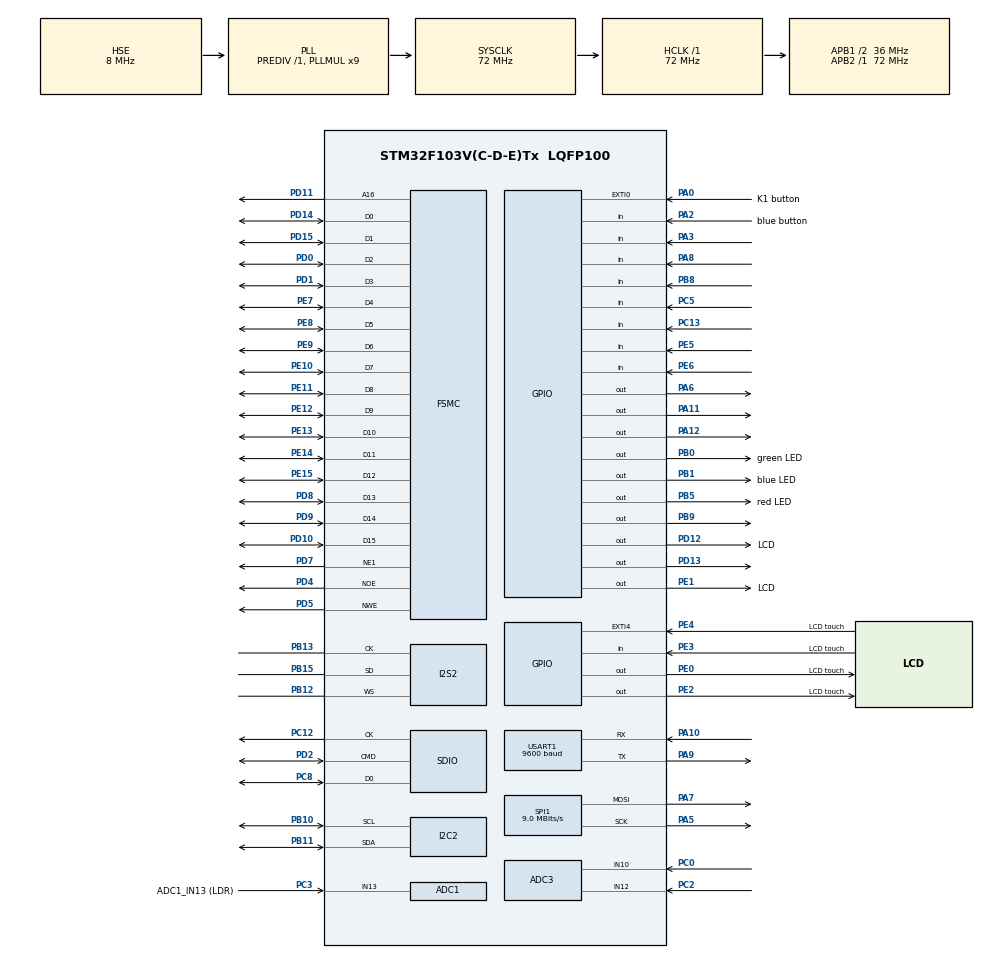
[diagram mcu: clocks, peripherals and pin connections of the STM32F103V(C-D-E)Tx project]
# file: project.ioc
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ADC1.Channel-0\#ChannelRegularConversion=ADC_CHANNEL_13
ADC1.NbrOfConversionFlag=1
ADC1.Rank-0\#ChannelRegularConversion=1
ADC1.SamplingTime-0\#ChannelRegularConversion=ADC_SAMPLETIME_1CYCLE_5
ADC1.master=1
ADC3.Channel-0\#ChannelRegularConversion=ADC_CHANNEL_10
ADC3.Channel-1\#ChannelRegularConversion=ADC_CHANNEL_12
ADC3.ContinuousConvMode=ENABLE
ADC3.NbrOfConversion=2
ADC3.NbrOfConversionFlag=1
ADC3.Rank-0\#ChannelRegularConversion=1
ADC3.Rank-1\#ChannelRegularConversion=2
ADC3.SamplingTime-0\#ChannelRegularConversion=ADC_SAMPLETIME_239CYCLES_5
ADC3.SamplingTime-1\#ChannelRegularConversion=ADC_SAMPLETIME_239CYCLES_5
Dma.ADC3.0.Direction=DMA_PERIPH_TO_MEMORY
Dma.ADC3.0.Instance=DMA2_Channel5
Dma.ADC3.0.MemDataAlignment=DMA_MDATAALIGN_WORD
Dma.ADC3.0.MemInc=DMA_MINC_ENABLE
Dma.ADC3.0.Mode=DMA_CIRCULAR
Dma.ADC3.0.PeriphDataAlignment=DMA_PDATAALIGN_WORD
Dma.ADC3.0.PeriphInc=DMA_PINC_DISABLE
Dma.ADC3.0.Priority=DMA_PRIORITY_LOW
Dma.Request0=ADC3
Dma.Request1=SPI2_TX
Dma.Request2=SPI1_TX
Dma.SPI1_TX.2.Direction=DMA_MEMORY_TO_PERIPH
Dma.SPI1_TX.2.Instance=DMA1_Channel3
Dma.SPI1_TX.2.MemDataAlignment=DMA_MDATAALIGN_BYTE
Dma.SPI1_TX.2.MemInc=DMA_MINC_ENABLE
Dma.SPI1_TX.2.Mode=DMA_NORMAL
Dma.SPI1_TX.2.PeriphDataAlignment=DMA_PDATAALIGN_BYTE
Dma.SPI1_TX.2.PeriphInc=DMA_PINC_DISABLE
Dma.SPI1_TX.2.Priority=DMA_PRIORITY_LOW
Dma.SPI2_TX.1.Direction=DMA_MEMORY_TO_PERIPH
Dma.SPI2_TX.1.Instance=DMA1_Channel5
Dma.SPI2_TX.1.MemDataAlignment=DMA_MDATAALIGN_HALFWORD
Dma.SPI2_TX.1.MemInc=DMA_MINC_ENABLE
Dma.SPI2_TX.1.Mode=DMA_CIRCULAR
Dma.SPI2_TX.1.PeriphDataAlignment=DMA_PDATAALIGN_HALFWORD
Dma.SPI2_TX.1.PeriphInc=DMA_PINC_DISABLE
Dma.SPI2_TX.1.Priority=DMA_PRIORITY_LOW
FATFS._MAX_SS=4096
I2C2.I2C_Mode=I2C_Fast
I2S2.AudioFreq=I2S_AUDIOFREQ_48K
I2S2.CPOL=I2S_CPOL_LOW
I2S2.DataFormat=I2S_DATAFORMAT_16B
I2S2.ErrorAudioFreq=-0.26 %
I2S2.Instance=SPI$Index
I2S2.RealAudioFreq=47.872 KHz
I2S2.VirtualMode=I2S_MODE_MASTER
Mcu.Family=STM32F1
Mcu.Name=STM32F103V(C-D-E)Tx
Mcu.Package=LQFP100
NVIC.DMA1_Channel3_IRQn=true\:0\:0\:false\:false\:true\:false\:true\:true
NVIC.DMA1_Channel5_IRQn=true\:0\:0\:false\:false\:true\:false\:true\:true
NVIC.DMA2_Channel4_5_IRQn=true\:0\:0\:true\:false\:true\:false\:true\:true
NVIC.EXTI0_IRQn=true\:0\:0\:true\:false\:true\:true\:true\:true
NVIC.EXTI4_IRQn=true\:0\:0\:true\:false\:true\:true\:true\:true
NVIC.PriorityGroup=NVIC_PRIORITYGROUP_4
NVIC.TIM3_IRQn=true\:1\:0\:true\:false\:true\:true\:true\:true
OSC_IN.Mode=HSE-External-Oscillator
OSC_IN.Signal=RCC_OSC_IN
OSC_OUT.Mode=HSE-External-Oscillator
OSC_OUT.Signal=RCC_OSC_OUT
PA0-WKUP.GPIO_Label=K1 button
PA0-WKUP.GPIO_ModeDefaultEXTI=GPIO_MODE_IT_RISING
PA0-WKUP.Signal=GPXTI0
PA10.Mode=Asynchronous
PA10.Signal=USART1_RX
PA11.GPIO_ModeDefaultOutputPP=GPIO_MODE_OUTPUT_PP
PA11.GPIO_Speed=GPIO_SPEED_FREQ_HIGH
PA11.PinState=GPIO_PIN_RESET
PA11.Signal=GPIO_Output
PA12.GPIO_Speed=GPIO_SPEED_FREQ_HIGH
PA12.Signal=GPIO_Output
PA13.Mode=Serial_Wire
PA13.Signal=SYS_JTMS-SWDIO
PA14.Mode=Serial_Wire
PA14.Signal=SYS_JTCK-SWCLK
PA2.GPIO_Label=blue button
PA2.GPIO_PuPd=GPIO_NOPULL
PA2.Signal=GPIO_Input
PA3.Signal=GPIO_Input
PA5.Mode=TX_Only_Simplex_Unidirect_Master
PA5.Signal=SPI1_SCK
PA6.GPIO_Speed=GPIO_SPEED_FREQ_HIGH
PA6.Signal=GPIO_Output
PA7.Mode=TX_Only_Simplex_Unidirect_Master
PA7.Signal=SPI1_MOSI
PA8.Signal=GPIO_Input
PA9.Mode=Asynchronous
PA9.Signal=USART1_TX
PB0.GPIO_Label=green LED
PB0.GPIO_Speed=GPIO_SPEED_FREQ_HIGH
PB0.PinState=GPIO_PIN_SET
PB0.Signal=GPIO_Output
PB1.GPIO_Label=blue LED
PB1.GPIO_Speed=GPIO_SPEED_FREQ_HIGH
PB1.PinState=GPIO_PIN_SET
PB1.Signal=GPIO_Output
PB10.Mode=I2C
PB10.Signal=I2C2_SCL
PB11.Mode=I2C
PB11.Signal=I2C2_SDA
PB12.Mode=Half_Duplex_Master_TX
PB12.Signal=I2S2_WS
PB13.Mode=Half_Duplex_Master_TX
PB13.Signal=I2S2_CK
PB15.Mode=Half_Duplex_Master_TX
PB15.Signal=I2S2_SD
PB5.GPIO_Label=red LED
PB5.GPIO_Speed=GPIO_SPEED_FREQ_HIGH
PB5.PinState=GPIO_PIN_SET
PB5.Signal=GPIO_Output
PB8.Signal=GPIO_Input
PB9.Signal=GPIO_Output
PC0.Signal=ADCx_IN10
PC12.Mode=SD_1_bit
PC12.Signal=SDIO_CK
PC13-TAMPER-RTC.Signal=GPIO_Input
PC14-OSC32_IN.Mode=LSE-External-Oscillator
PC14-OSC32_IN.Signal=RCC_OSC32_IN
PC15-OSC32_OUT.Mode=LSE-External-Oscillator
PC15-OSC32_OUT.Signal=RCC_OSC32_OUT
PC2.Signal=ADCx_IN12
PC3.GPIO_Label=ADC1_IN13 (LDR)
PC3.Signal=ADCx_IN13
PC5.Signal=GPIO_Input
PC8.Mode=SD_1_bit
PC8.Signal=SDIO_D0
PD0.Mode=16b-d1
PD0.Signal=FSMC_D2
PD1.Mode=16b-d1
PD1.Signal=FSMC_D3
PD10.Mode=16b-d1
PD10.Signal=FSMC_D15
PD11.Mode=A16_1
PD11.Signal=FSMC_A16
PD12.GPIO_Label=LCD
PD12.GPIO_Speed=GPIO_SPEED_FREQ_HIGH
PD12.Signal=GPIO_Output
PD13.GPIO_Speed=GPIO_SPEED_FREQ_HIGH
PD13.Signal=GPIO_Output
PD14.Mode=16b-d1
PD14.Signal=FSMC_D0
PD15.Mode=16b-d1
PD15.Signal=FSMC_D1
PD2.Mode=SD_1_bit
PD2.Signal=SDIO_CMD
PD4.Mode=Lcd1
PD4.Signal=FSMC_NOE
PD5.Mode=Lcd1
PD5.Signal=FSMC_NWE
PD7.Mode=NorPsramChipSelect1_1
PD7.Signal=FSMC_NE1
PD8.Mode=16b-d1
PD8.Signal=FSMC_D13
PD9.Mode=16b-d1
PD9.Signal=FSMC_D14
PE0.GPIO_Label=LCD touch
PE0.GPIO_Speed=GPIO_SPEED_FREQ_HIGH
PE0.Signal=GPIO_Output
PE1.GPIO_Label=LCD
PE1.GPIO_Speed=GPIO_SPEED_FREQ_HIGH
PE1.Signal=GPIO_Output
PE10.Mode=16b-d1
PE10.Signal=FSMC_D7
PE11.Mode=16b-d1
PE11.Signal=FSMC_D8
PE12.Mode=16b-d1
PE12.Signal=FSMC_D9
PE13.Mode=16b-d1
PE13.Signal=FSMC_D10
PE14.Mode=16b-d1
PE14.Signal=FSMC_D11
PE15.Mode=16b-d1
PE15.Signal=FSMC_D12
PE2.GPIO_Label=LCD touch
PE2.GPIO_Speed=GPIO_SPEED_FREQ_HIGH
PE2.Signal=GPIO_Output
PE3.GPIO_Label=LCD touch
PE3.GPIO_PuPd=GPIO_PULLUP
PE3.Signal=GPIO_Input
PE4.GPIO_Label=LCD touch
PE4.Signal=GPXTI4
PE5.Signal=GPIO_Input
PE6.Signal=GPIO_Input
PE7.Mode=16b-d1
PE7.Signal=FSMC_D4
PE8.Mode=16b-d1
PE8.Signal=FSMC_D5
PE9.Mode=16b-d1
PE9.Signal=FSMC_D6
ProjectManager.HeapSize=0x200
ProjectManager.StackSize=0x400
ProjectManager.TargetToolchain=STM32CubeIDE
RCC.ADCPresc=RCC_ADCPCLK2_DIV6
RCC.AHBFreq_Value=72000000
RCC.APB1CLKDivider=RCC_HCLK_DIV2
RCC.APB1Freq_Value=36000000
RCC.APB1TimFreq_Value=72000000
RCC.APB2Freq_Value=72000000
RCC.APB2TimFreq_Value=72000000
RCC.HCLKFreq_Value=72000000
RCC.PLLMUL=RCC_PLL_MUL9
RCC.PLLSourceVirtual=RCC_PLLSOURCE_HSE
RCC.SYSCLKFreq_VALUE=72000000
RCC.SYSCLKSource=RCC_SYSCLKSOURCE_PLLCLK
RCC.USBFreq_Value=72000000
SDIO.ClockDiv=6
SDIO.HardwareFlowControl=SDIO_HARDWARE_FLOW_CONTROL_ENABLE
SH.ADCx_IN10.0=ADC3_IN10,IN10
SH.ADCx_IN12.0=ADC3_IN12,IN12
SH.ADCx_IN13.0=ADC1_IN13,IN13
SPI1.BaudRatePrescaler=SPI_BAUDRATEPRESCALER_8
SPI1.CalculateBaudRate=9.0 MBits/s
SPI1.Direction=SPI_DIRECTION_2LINES
SPI1.Mode=SPI_MODE_MASTER
SPI1.VirtualType=VM_MASTER
TIM1.Period=0xffff-1
TIM1.Prescaler=72-1
TIM2.Prescaler=71
TIM3.Period=10000
TIM3.Prescaler=7199
USART1.BaudRate=9600
USART1.VirtualMode=VM_ASYNC
VP_FATFS_VS_SDIO.Mode=SDIO
VP_TIM1_VS_ClockSourceINT.Mode=Internal
VP_TIM2_VS_ClockSourceINT.Mode=Internal
VP_TIM3_VS_ClockSourceINT.Mode=Internal
board=custom

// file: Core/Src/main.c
/* USER CODE BEGIN Header */
/**
  ******************************************************************************
  * @file           : main.c
  * @brief          : Main program body
  ******************************************************************************
  * @attention
  *
  * Copyright (c) 2024 STMicroelectronics.
  * All rights reserved.
  *
  * This software is licensed under terms that can be found in the LICENSE file
  * in the root directory of this software component.
  * If no LICENSE file comes with this software, it is provided AS-IS.
  *
  ******************************************************************************
  */
/* USER CODE END Header */
#include "main.h"
#include "fatfs.h"

/* USER CODE BEGIN Includes */
#include "maze.h"
#include "move.h"
#include "xpt2046.h"
#include "max7219.h"
#include "game.h"
#include <stdbool.h>
#include "mpu.h"
/* USER CODE END Includes */

 ADC_HandleTypeDef hadc1;
ADC_HandleTypeDef hadc3;
DMA_HandleTypeDef hdma_adc3;

I2C_HandleTypeDef hi2c2;

I2S_HandleTypeDef hi2s2;
DMA_HandleTypeDef hdma_spi2_tx;

SD_HandleTypeDef hsd;

SPI_HandleTypeDef hspi1;
DMA_HandleTypeDef hdma_spi1_tx;

TIM_HandleTypeDef htim1;
TIM_HandleTypeDef htim2;
TIM_HandleTypeDef htim3;

UART_HandleTypeDef huart1;

SRAM_HandleTypeDef hsram1;

/* USER CODE BEGIN PV */

 //*** start_x, start_y. rows, columns -> need to be odd(for generate_maze algo)***
 uint8_t **maze;	//dynamically allocated array
 uint8_t rows, columns, start_x, end_x, start_y, end_y, current_x, current_y, next_x, next_y;
 uint8_t hearts;
 uint8_t keys = 0;
 uint8_t end = 0; // 0 - not end //1 - win //2 - lose
 uint8_t restart_flag = 0;	//for k1/win/lose check for next round
 volatile int timer = -1;	//mark the count down timer
 volatile int tim = 0;
 uint8_t duration = -1;
 const uint8_t block_size = 16;
 uint32_t joy[] = {0,0};

 volatile bool fail = false;

 uint8_t Rxstr;

 const uint8_t key[] = //24x32
 {
 0x00, 0x00, 0xf8, 0x07, 0x00, 0x00, 0xff, 0x0f, 0x00,
 0x80, 0xff, 0x1f, 0x00, 0xc0, 0xff, 0x3f, 0x00, 0xc0,
 0xff, 0x3f, 0x00, 0xc0, 0xff, 0x7f, 0x00, 0xc0, 0xff,
 0x7f, 0x00, 0xc0, 0xff, 0x7f, 0x00, 0xc0, 0xff, 0x3f,
 0x00, 0xc0, 0xff, 0x3f, 0x00, 0xc0, 0xff, 0x1f, 0x00,
 0xf0, 0xff, 0x0f, 0x00, 0xf8, 0xff, 0x07, 0x00, 0xfc,
 0xff, 0x01, 0x00, 0x7e, 0x00, 0x00, 0x00, 0x3f, 0x00,
 0x00, 0xc0, 0x1f, 0x00, 0x00, 0xe0, 0x07, 0x00, 0x00,
 0xf0, 0x03, 0x00, 0x00, 0xf8, 0x00, 0x00, 0x00, 0x7c,
 0x00, 0x00, 0x00, 0x1c, 0x00, 0x00, 0x00, 0x00, 0x00,
 0x00, 0x00, 0x00, 0x00, 0x00, 0x00
 };

 const uint8_t heart[] =	//24x32
 {
 0xf8, 0x01, 0x80, 0x1f, 0xfc, 0x03, 0xf0, 0x3f, 0xfc,
 0x0f, 0xf8, 0x3f, 0xfe, 0x1f, 0xfc, 0x7f, 0xfe, 0x3f,
 0xfc, 0x7f, 0xfe, 0x7f, 0xfe, 0x7f, 0xfe, 0xff, 0xff,
 0x7f, 0xfe, 0xff, 0xff, 0x7f, 0xfc, 0xff, 0xff, 0x3f,
 0xfc, 0xff, 0xff, 0x3f, 0xfc, 0xff, 0xff, 0x3f, 0xf8,
 0xff, 0xff, 0x1f, 0xf8, 0xff, 0xff, 0x1f, 0xf0, 0xff,
 0xff, 0x0f, 0xf0, 0xff, 0xff, 0x07, 0xe0, 0xff, 0xff,
 0x03, 0xe0, 0xff, 0xff, 0x01, 0xc0, 0xff, 0xff, 0x01,
 0x80, 0xff, 0xff, 0x00, 0x00, 0xfe, 0x7f, 0x00, 0x00,
 0xfc, 0x3f, 0x00, 0x00, 0xf8, 0x1f, 0x00, 0x00, 0xf0,
 0x1f, 0x00, 0x00, 0xc0, 0x07, 0x00
 };

 const uint8_t start[] =	//16x16
 {
 0xc0, 0x03, 0xe0, 0x0f, 0xf0, 0x1f, 0xf8, 0x1f, 0xf8, 0x1f, 0xf8, 0x1f, 0xf8, 0x1f, 0xf0, 0x0f, 0xc0, 0x07, 0xf0, 0x1f, 0xd8, 0x37, 0xcc, 0x67, 0xc0, 0x07, 0xc0, 0x06, 0xc0, 0x06, 0xc0, 0x06
 };
 const uint8_t endpt[] =
 {
 0x00, 0x00, 0x00, 0x00, 0x38, 0x20, 0xfe, 0x38, 0xfe, 0x3f, 0xfe, 0x3f, 0xfe, 0x3f, 0xfe, 0x3f, 0xfe, 0x3f, 0xc6, 0x3f, 0x00, 0x3f, 0x00, 0x30, 0x00, 0x30, 0x00, 0x30, 0x00, 0x30, 0x00, 0x30
 };
 const uint8_t elekey[] =
 {
 0x00, 0x00, 0x00, 0x3f, 0xc0, 0x7f, 0xc0, 0x7f, 0xc0, 0xff, 0xc0, 0xff, 0xc0, 0xff, 0x80, 0xff, 0xc0, 0x7f, 0xe0, 0x3d, 0xf0, 0x01, 0xf8, 0x00, 0x3c, 0x00, 0x1e, 0x00, 0x0e, 0x00, 0x00, 0x00
 };
 const uint8_t game[] =
 {
 0xc0, 0x01, 0xe0, 0x03, 0xf0, 0x07, 0xf0, 0x07, 0xf0, 0x07, 0xf0, 0x07, 0xf0, 0x07, 0xf0, 0x07, 0xf0, 0x07, 0xe0, 0x03, 0xe0, 0x03, 0xe0, 0x03, 0xc0, 0x01, 0x00, 0x00, 0xc0, 0x01, 0xc0, 0x01
 };
 const uint8_t event[] =
 {
 0xc0, 0x07, 0xf0, 0x1f, 0xf8, 0x3f, 0x3c, 0x38, 0x1c, 0x38, 0x1c, 0x1e, 0x00, 0x1f, 0xc0, 0x0f, 0xc0, 0x03, 0xc0, 0x01, 0xc0, 0x01, 0xc0, 0x01, 0xc0, 0x01, 0x00, 0x00, 0xc0, 0x01, 0xc0, 0x01
 };
 const uint8_t sheart[] =
 {
 0x00, 0x00, 0x1c, 0x38, 0x3e, 0x7c, 0x7f, 0xfe, 0xff, 0xff, 0xff, 0xff, 0xfe, 0x7f, 0xfe, 0x7f, 0xfc, 0x3f, 0xf8, 0x1f, 0xf0, 0x0f, 0xe0, 0x07, 0xe0, 0x03, 0xc0, 0x03, 0x80, 0x01, 0x00, 0x00
 };
 const uint8_t toxic[] =
 {
 0x00, 0x00, 0xf0, 0x07, 0xf9, 0x4f, 0xcf, 0x79, 0xcf, 0x79, 0xcc, 0x19, 0xf8, 0x0f, 0x7c, 0x1f, 0x3e, 0x3e, 0xff, 0x7f, 0xe3, 0x63, 0xe1, 0x43, 0xc0, 0x01, 0x00, 0x00, 0x00, 0x00, 0x00, 0x00
 };
 const uint8_t random_move[] =
 {
 0x58, 0x04, 0x98, 0x84, 0x30, 0xcd, 0xe3, 0x6f, 0xfe, 0x1f, 0xfc, 0xef, 0xfc, 0x3f, 0xfe, 0x1f, 0xff, 0x1f, 0xf8, 0x7f, 0xfe, 0x8f, 0xf2, 0x1b, 0xb9, 0x19, 0x18, 0x33, 0x08, 0x03, 0x00, 0x02
 };

/* USER CODE END PV */

void SystemClock_Config(void);
static void MX_GPIO_Init(void);
static void MX_FSMC_Init(void);
static void MX_ADC1_Init(void);
static void MX_TIM3_Init(void);
static void MX_TIM1_Init(void);
static void MX_I2S2_Init(void);
static void MX_SDIO_SD_Init(void);
static void MX_DMA_Init(void);
static void MX_ADC3_Init(void);
static void MX_SPI1_Init(void);
static void MX_USART1_UART_Init(void);
static void MX_TIM2_Init(void);
static void MX_I2C2_Init(void);
/* USER CODE BEGIN PFP */
void HAL_I2S_TxHalfCpltCallback(I2S_HandleTypeDef *hi2s);
void HAL_I2S_TxCpltCallback(I2S_HandleTypeDef *hi2s);
/* USER CODE END PFP */

int main(void)
{

  /* MCU Configuration--------------------------------------------------------*/

  /* Reset of all peripherals, Initializes the Flash interface and the Systick. */
  HAL_Init();

  /* Configure the system clock */
  SystemClock_Config();

  /* Initialize all configured peripherals */
  MX_GPIO_Init();
  MX_FSMC_Init();
  MX_DMA_Init();
  MX_ADC1_Init();
  MX_TIM3_Init();
  MX_TIM1_Init();
  MX_I2S2_Init();
  MX_SDIO_SD_Init();
  MX_ADC3_Init();
  MX_FATFS_Init();
  MX_SPI1_Init();
  MX_USART1_UART_Init();
  MX_TIM2_Init();
  MX_I2C2_Init();
  /* USER CODE BEGIN 2 */
  MPU6050_Init ();
  macXPT2046_CS_DISABLE();
  LCD_INIT();
  HAL_TIM_Base_Start_IT(&htim3);
  HAL_TIM_Base_Start_IT(&htim1);
  HAL_ADCEx_Calibration_Start(&hadc1);	//adc calibration
  HAL_ADCEx_Calibration_Start(&hadc3);	//adc calibration
  HAL_ADC_Start_DMA(&hadc3, joy, 2);
  max7219_Init();
  //HAL_ADC_Stop(&hadc3);
  HAL_TIM_Base_Start(&htim2);

  /* USER CODE END 2 */

  /* Infinite loop */
  /* USER CODE BEGIN WHILE */

  while( ! XPT2046_Touch_Calibrate () );

  setRandomSeed();	//random the seed
  maze_all();

  //interrupt - k1 -> next round

  while (1)
  {
	  //handle movement
	 move();
    /* USER CODE END WHILE */

  }
}

void SystemClock_Config(void)
{
  RCC_OscInitTypeDef RCC_OscInitStruct = {0};
  RCC_ClkInitTypeDef RCC_ClkInitStruct = {0};
  RCC_PeriphCLKInitTypeDef PeriphClkInit = {0};

  /** Initializes the RCC Oscillators according to the specified parameters
  * in the RCC_OscInitTypeDef structure.
  */
  RCC_OscInitStruct.OscillatorType = RCC_OSCILLATORTYPE_HSE;
  RCC_OscInitStruct.HSEState = RCC_HSE_ON;
  RCC_OscInitStruct.HSEPredivValue = RCC_HSE_PREDIV_DIV1;
  RCC_OscInitStruct.HSIState = RCC_HSI_ON;
  RCC_OscInitStruct.PLL.PLLState = RCC_PLL_ON;
  RCC_OscInitStruct.PLL.PLLSource = RCC_PLLSOURCE_HSE;
  RCC_OscInitStruct.PLL.PLLMUL = RCC_PLL_MUL9;
  if (HAL_RCC_OscConfig(&RCC_OscInitStruct) != HAL_OK)
  {
    Error_Handler();
  }

  /** Initializes the CPU, AHB and APB buses clocks
  */
  RCC_ClkInitStruct.ClockType = RCC_CLOCKTYPE_HCLK|RCC_CLOCKTYPE_SYSCLK
                              |RCC_CLOCKTYPE_PCLK1|RCC_CLOCKTYPE_PCLK2;
  RCC_ClkInitStruct.SYSCLKSource = RCC_SYSCLKSOURCE_PLLCLK;
  RCC_ClkInitStruct.AHBCLKDivider = RCC_SYSCLK_DIV1;
  RCC_ClkInitStruct.APB1CLKDivider = RCC_HCLK_DIV2;
  RCC_ClkInitStruct.APB2CLKDivider = RCC_HCLK_DIV1;

  if (HAL_RCC_ClockConfig(&RCC_ClkInitStruct, FLASH_LATENCY_2) != HAL_OK)
  {
    Error_Handler();
  }
  PeriphClkInit.PeriphClockSelection = RCC_PERIPHCLK_ADC|RCC_PERIPHCLK_I2S2;
  PeriphClkInit.AdcClockSelection = RCC_ADCPCLK2_DIV6;
  PeriphClkInit.I2s2ClockSelection = RCC_I2S2CLKSOURCE_SYSCLK;
  if (HAL_RCCEx_PeriphCLKConfig(&PeriphClkInit) != HAL_OK)
  {
    Error_Handler();
  }
}

static void MX_ADC1_Init(void)
{

  ADC_ChannelConfTypeDef sConfig = {0};

  /** Common config
  */
  hadc1.Instance = ADC1;
  hadc1.Init.ScanConvMode = ADC_SCAN_DISABLE;
  hadc1.Init.ContinuousConvMode = DISABLE;
  hadc1.Init.DiscontinuousConvMode = DISABLE;
  hadc1.Init.ExternalTrigConv = ADC_SOFTWARE_START;
  hadc1.Init.DataAlign = ADC_DATAALIGN_RIGHT;
  hadc1.Init.NbrOfConversion = 1;
  if (HAL_ADC_Init(&hadc1) != HAL_OK)
  {
    Error_Handler();
  }

  /** Configure Regular Channel
  */
  sConfig.Channel = ADC_CHANNEL_13;
  sConfig.Rank = ADC_REGULAR_RANK_1;
  sConfig.SamplingTime = ADC_SAMPLETIME_1CYCLE_5;
  if (HAL_ADC_ConfigChannel(&hadc1, &sConfig) != HAL_OK)
  {
    Error_Handler();
  }

}

static void MX_ADC3_Init(void)
{

  ADC_ChannelConfTypeDef sConfig = {0};

  /** Common config
  */
  hadc3.Instance = ADC3;
  hadc3.Init.ScanConvMode = ADC_SCAN_ENABLE;
  hadc3.Init.ContinuousConvMode = ENABLE;
  hadc3.Init.DiscontinuousConvMode = DISABLE;
  hadc3.Init.ExternalTrigConv = ADC_SOFTWARE_START;
  hadc3.Init.DataAlign = ADC_DATAALIGN_RIGHT;
  hadc3.Init.NbrOfConversion = 2;
  if (HAL_ADC_Init(&hadc3) != HAL_OK)
  {
    Error_Handler();
  }

  /** Configure Regular Channel
  */
  sConfig.Channel = ADC_CHANNEL_10;
  sConfig.Rank = ADC_REGULAR_RANK_1;
  sConfig.SamplingTime = ADC_SAMPLETIME_239CYCLES_5;
  if (HAL_ADC_ConfigChannel(&hadc3, &sConfig) != HAL_OK)
  {
    Error_Handler();
  }

  /** Configure Regular Channel
  */
  sConfig.Channel = ADC_CHANNEL_12;
  sConfig.Rank = ADC_REGULAR_RANK_2;
  if (HAL_ADC_ConfigChannel(&hadc3, &sConfig) != HAL_OK)
  {
    Error_Handler();
  }

}

static void MX_I2C2_Init(void)
{

  hi2c2.Instance = I2C2;
  hi2c2.Init.ClockSpeed = 400000;
  hi2c2.Init.DutyCycle = I2C_DUTYCYCLE_2;
  hi2c2.Init.OwnAddress1 = 0;
  hi2c2.Init.AddressingMode = I2C_ADDRESSINGMODE_7BIT;
  hi2c2.Init.DualAddressMode = I2C_DUALADDRESS_DISABLE;
  hi2c2.Init.OwnAddress2 = 0;
  hi2c2.Init.GeneralCallMode = I2C_GENERALCALL_DISABLE;
  hi2c2.Init.NoStretchMode = I2C_NOSTRETCH_DISABLE;
  if (HAL_I2C_Init(&hi2c2) != HAL_OK)
  {
    Error_Handler();
  }

}

static void MX_I2S2_Init(void)
{

  hi2s2.Instance = SPI2;
  hi2s2.Init.Mode = I2S_MODE_MASTER_TX;
  hi2s2.Init.Standard = I2S_STANDARD_PHILIPS;
  hi2s2.Init.DataFormat = I2S_DATAFORMAT_16B;
  hi2s2.Init.MCLKOutput = I2S_MCLKOUTPUT_DISABLE;
  hi2s2.Init.AudioFreq = I2S_AUDIOFREQ_48K;
  hi2s2.Init.CPOL = I2S_CPOL_LOW;
  if (HAL_I2S_Init(&hi2s2) != HAL_OK)
  {
    Error_Handler();
  }

}

static void MX_SDIO_SD_Init(void)
{

  hsd.Instance = SDIO;
  hsd.Init.ClockEdge = SDIO_CLOCK_EDGE_RISING;
  hsd.Init.ClockBypass = SDIO_CLOCK_BYPASS_DISABLE;
  hsd.Init.ClockPowerSave = SDIO_CLOCK_POWER_SAVE_DISABLE;
  hsd.Init.BusWide = SDIO_BUS_WIDE_1B;
  hsd.Init.HardwareFlowControl = SDIO_HARDWARE_FLOW_CONTROL_ENABLE;
  hsd.Init.ClockDiv = 6;
  /* USER CODE BEGIN SDIO_Init 2 */
  if (HAL_SD_Init(&hsd) != HAL_OK){Error_Handler();}
  if (HAL_SD_ConfigWideBusOperation(&hsd, SDIO_BUS_WIDE_4B) != HAL_OK){Error_Handler();}
  /* USER CODE END SDIO_Init 2 */

}

static void MX_SPI1_Init(void)
{

  /* SPI1 parameter configuration*/
  hspi1.Instance = SPI1;
  hspi1.Init.Mode = SPI_MODE_MASTER;
  hspi1.Init.Direction = SPI_DIRECTION_2LINES;
  hspi1.Init.DataSize = SPI_DATASIZE_8BIT;
  hspi1.Init.CLKPolarity = SPI_POLARITY_LOW;
  hspi1.Init.CLKPhase = SPI_PHASE_1EDGE;
  hspi1.Init.NSS = SPI_NSS_SOFT;
  hspi1.Init.BaudRatePrescaler = SPI_BAUDRATEPRESCALER_8;
  hspi1.Init.FirstBit = SPI_FIRSTBIT_MSB;
  hspi1.Init.TIMode = SPI_TIMODE_DISABLE;
  hspi1.Init.CRCCalculation = SPI_CRCCALCULATION_DISABLE;
  hspi1.Init.CRCPolynomial = 10;
  if (HAL_SPI_Init(&hspi1) != HAL_OK)
  {
    Error_Handler();
  }

}

static void MX_TIM1_Init(void)
{

  TIM_ClockConfigTypeDef sClockSourceConfig = {0};
  TIM_MasterConfigTypeDef sMasterConfig = {0};

  htim1.Instance = TIM1;
  htim1.Init.Prescaler = 72-1;
  htim1.Init.CounterMode = TIM_COUNTERMODE_UP;
  htim1.Init.Period = 0xffff-1;
  htim1.Init.ClockDivision = TIM_CLOCKDIVISION_DIV1;
  htim1.Init.RepetitionCounter = 0;
  htim1.Init.AutoReloadPreload = TIM_AUTORELOAD_PRELOAD_DISABLE;
  if (HAL_TIM_Base_Init(&htim1) != HAL_OK)
  {
    Error_Handler();
  }
  sClockSourceConfig.ClockSource = TIM_CLOCKSOURCE_INTERNAL;
  if (HAL_TIM_ConfigClockSource(&htim1, &sClockSourceConfig) != HAL_OK)
  {
    Error_Handler();
  }
  sMasterConfig.MasterOutputTrigger = TIM_TRGO_RESET;
  sMasterConfig.MasterSlaveMode = TIM_MASTERSLAVEMODE_DISABLE;
  if (HAL_TIMEx_MasterConfigSynchronization(&htim1, &sMasterConfig) != HAL_OK)
  {
    Error_Handler();
  }

}

static void MX_TIM2_Init(void)
{

  TIM_ClockConfigTypeDef sClockSourceConfig = {0};
  TIM_MasterConfigTypeDef sMasterConfig = {0};

  htim2.Instance = TIM2;
  htim2.Init.Prescaler = 71;
  htim2.Init.CounterMode = TIM_COUNTERMODE_UP;
  htim2.Init.Period = 65535;
  htim2.Init.ClockDivision = TIM_CLOCKDIVISION_DIV1;
  htim2.Init.AutoReloadPreload = TIM_AUTORELOAD_PRELOAD_DISABLE;
  if (HAL_TIM_Base_Init(&htim2) != HAL_OK)
  {
    Error_Handler();
  }
  sClockSourceConfig.ClockSource = TIM_CLOCKSOURCE_INTERNAL;
  if (HAL_TIM_ConfigClockSource(&htim2, &sClockSourceConfig) != HAL_OK)
  {
    Error_Handler();
  }
  sMasterConfig.MasterOutputTrigger = TIM_TRGO_RESET;
  sMasterConfig.MasterSlaveMode = TIM_MASTERSLAVEMODE_DISABLE;
  if (HAL_TIMEx_MasterConfigSynchronization(&htim2, &sMasterConfig) != HAL_OK)
  {
    Error_Handler();
  }

}

static void MX_TIM3_Init(void)
{

  TIM_ClockConfigTypeDef sClockSourceConfig = {0};
  TIM_MasterConfigTypeDef sMasterConfig = {0};

  htim3.Instance = TIM3;
  htim3.Init.Prescaler = 7199;
  htim3.Init.CounterMode = TIM_COUNTERMODE_UP;
  htim3.Init.Period = 10000;
  htim3.Init.ClockDivision = TIM_CLOCKDIVISION_DIV1;
  htim3.Init.AutoReloadPreload = TIM_AUTORELOAD_PRELOAD_DISABLE;
  if (HAL_TIM_Base_Init(&htim3) != HAL_OK)
  {
    Error_Handler();
  }
  sClockSourceConfig.ClockSource = TIM_CLOCKSOURCE_INTERNAL;
  if (HAL_TIM_ConfigClockSource(&htim3, &sClockSourceConfig) != HAL_OK)
  {
    Error_Handler();
  }
  sMasterConfig.MasterOutputTrigger = TIM_TRGO_RESET;
  sMasterConfig.MasterSlaveMode = TIM_MASTERSLAVEMODE_DISABLE;
  if (HAL_TIMEx_MasterConfigSynchronization(&htim3, &sMasterConfig) != HAL_OK)
  {
    Error_Handler();
  }

}

static void MX_USART1_UART_Init(void)
{

  huart1.Instance = USART1;
  huart1.Init.BaudRate = 9600;
  huart1.Init.WordLength = UART_WORDLENGTH_8B;
  huart1.Init.StopBits = UART_STOPBITS_1;
  huart1.Init.Parity = UART_PARITY_NONE;
  huart1.Init.Mode = UART_MODE_TX_RX;
  huart1.Init.HwFlowCtl = UART_HWCONTROL_NONE;
  huart1.Init.OverSampling = UART_OVERSAMPLING_16;
  if (HAL_UART_Init(&huart1) != HAL_OK)
  {
    Error_Handler();
  }

}

static void MX_DMA_Init(void)
{

  /* DMA controller clock enable */
  __HAL_RCC_DMA2_CLK_ENABLE();
  __HAL_RCC_DMA1_CLK_ENABLE();

  /* DMA interrupt init */
  /* DMA1_Channel3_IRQn interrupt configuration */
  HAL_NVIC_SetPriority(DMA1_Channel3_IRQn, 0, 0);
  HAL_NVIC_EnableIRQ(DMA1_Channel3_IRQn);
  /* DMA1_Channel5_IRQn interrupt configuration */
  HAL_NVIC_SetPriority(DMA1_Channel5_IRQn, 0, 0);
  HAL_NVIC_EnableIRQ(DMA1_Channel5_IRQn);
  /* DMA2_Channel4_5_IRQn interrupt configuration */
  HAL_NVIC_SetPriority(DMA2_Channel4_5_IRQn, 0, 0);
  HAL_NVIC_EnableIRQ(DMA2_Channel4_5_IRQn);

}

static void MX_GPIO_Init(void)
{
  GPIO_InitTypeDef GPIO_InitStruct = {0};

  /* GPIO Ports Clock Enable */
  __HAL_RCC_GPIOE_CLK_ENABLE();
  __HAL_RCC_GPIOC_CLK_ENABLE();
  __HAL_RCC_GPIOA_CLK_ENABLE();
  __HAL_RCC_GPIOB_CLK_ENABLE();
  __HAL_RCC_GPIOD_CLK_ENABLE();

  /*Configure GPIO pin Output Level */
  HAL_GPIO_WritePin(GPIOE, LCD_touch_Pin|LCD_touchE0_Pin|LCDE1_Pin, GPIO_PIN_RESET);

  /*Configure GPIO pin Output Level */
  HAL_GPIO_WritePin(GPIOA, GPIO_PIN_6|GPIO_PIN_11|GPIO_PIN_12, GPIO_PIN_RESET);

  /*Configure GPIO pin Output Level */
  HAL_GPIO_WritePin(GPIOB, green_LED_Pin|blue_LED_Pin|red_LED_Pin, GPIO_PIN_SET);

  /*Configure GPIO pin Output Level */
  HAL_GPIO_WritePin(GPIOD, LCD_Pin|GPIO_PIN_13, GPIO_PIN_RESET);

  /*Configure GPIO pin Output Level */
  HAL_GPIO_WritePin(GPIOB, GPIO_PIN_9, GPIO_PIN_RESET);

  /*Configure GPIO pins : LCD_touch_Pin LCD_touchE0_Pin LCDE1_Pin */
  GPIO_InitStruct.Pin = LCD_touch_Pin|LCD_touchE0_Pin|LCDE1_Pin;
  GPIO_InitStruct.Mode = GPIO_MODE_OUTPUT_PP;
  GPIO_InitStruct.Pull = GPIO_NOPULL;
  GPIO_InitStruct.Speed = GPIO_SPEED_FREQ_HIGH;
  HAL_GPIO_Init(GPIOE, &GPIO_InitStruct);

  /*Configure GPIO pin : LCD_touchE3_Pin */
  GPIO_InitStruct.Pin = LCD_touchE3_Pin;
  GPIO_InitStruct.Mode = GPIO_MODE_INPUT;
  GPIO_InitStruct.Pull = GPIO_PULLUP;
  HAL_GPIO_Init(LCD_touchE3_GPIO_Port, &GPIO_InitStruct);

  /*Configure GPIO pin : LCD_touchE4_Pin */
  GPIO_InitStruct.Pin = LCD_touchE4_Pin;
  GPIO_InitStruct.Mode = GPIO_MODE_IT_RISING;
  GPIO_InitStruct.Pull = GPIO_NOPULL;
  HAL_GPIO_Init(LCD_touchE4_GPIO_Port, &GPIO_InitStruct);

  /*Configure GPIO pins : PE5 PE6 */
  GPIO_InitStruct.Pin = GPIO_PIN_5|GPIO_PIN_6;
  GPIO_InitStruct.Mode = GPIO_MODE_INPUT;
  GPIO_InitStruct.Pull = GPIO_NOPULL;
  HAL_GPIO_Init(GPIOE, &GPIO_InitStruct);

  /*Configure GPIO pins : PC13 PC5 */
  GPIO_InitStruct.Pin = GPIO_PIN_13|GPIO_PIN_5;
  GPIO_InitStruct.Mode = GPIO_MODE_INPUT;
  GPIO_InitStruct.Pull = GPIO_NOPULL;
  HAL_GPIO_Init(GPIOC, &GPIO_InitStruct);

  /*Configure GPIO pin : K1_button_Pin */
  GPIO_InitStruct.Pin = K1_button_Pin;
  GPIO_InitStruct.Mode = GPIO_MODE_IT_RISING;
  GPIO_InitStruct.Pull = GPIO_NOPULL;
  HAL_GPIO_Init(K1_button_GPIO_Port, &GPIO_InitStruct);

  /*Configure GPIO pins : blue_button_Pin PA3 PA8 */
  GPIO_InitStruct.Pin = blue_button_Pin|GPIO_PIN_3|GPIO_PIN_8;
  GPIO_InitStruct.Mode = GPIO_MODE_INPUT;
  GPIO_InitStruct.Pull = GPIO_NOPULL;
  HAL_GPIO_Init(GPIOA, &GPIO_InitStruct);

  /*Configure GPIO pins : PA6 PA11 PA12 */
  GPIO_InitStruct.Pin = GPIO_PIN_6|GPIO_PIN_11|GPIO_PIN_12;
  GPIO_InitStruct.Mode = GPIO_MODE_OUTPUT_PP;
  GPIO_InitStruct.Pull = GPIO_NOPULL;
  GPIO_InitStruct.Speed = GPIO_SPEED_FREQ_HIGH;
  HAL_GPIO_Init(GPIOA, &GPIO_InitStruct);

  /*Configure GPIO pins : green_LED_Pin blue_LED_Pin red_LED_Pin */
  GPIO_InitStruct.Pin = green_LED_Pin|blue_LED_Pin|red_LED_Pin;
  GPIO_InitStruct.Mode = GPIO_MODE_OUTPUT_PP;
  GPIO_InitStruct.Pull = GPIO_NOPULL;
  GPIO_InitStruct.Speed = GPIO_SPEED_FREQ_HIGH;
  HAL_GPIO_Init(GPIOB, &GPIO_InitStruct);

  /*Configure GPIO pins : LCD_Pin PD13 */
  GPIO_InitStruct.Pin = LCD_Pin|GPIO_PIN_13;
  GPIO_InitStruct.Mode = GPIO_MODE_OUTPUT_PP;
  GPIO_InitStruct.Pull = GPIO_NOPULL;
  GPIO_InitStruct.Speed = GPIO_SPEED_FREQ_HIGH;
  HAL_GPIO_Init(GPIOD, &GPIO_InitStruct);

  /*Configure GPIO pin : PB8 */
  GPIO_InitStruct.Pin = GPIO_PIN_8;
  GPIO_InitStruct.Mode = GPIO_MODE_INPUT;
  GPIO_InitStruct.Pull = GPIO_NOPULL;
  HAL_GPIO_Init(GPIOB, &GPIO_InitStruct);

  /*Configure GPIO pin : PB9 */
  GPIO_InitStruct.Pin = GPIO_PIN_9;
  GPIO_InitStruct.Mode = GPIO_MODE_OUTPUT_PP;
  GPIO_InitStruct.Pull = GPIO_NOPULL;
  GPIO_InitStruct.Speed = GPIO_SPEED_FREQ_LOW;
  HAL_GPIO_Init(GPIOB, &GPIO_InitStruct);

  /* EXTI interrupt init*/
  HAL_NVIC_SetPriority(EXTI0_IRQn, 0, 0);
  HAL_NVIC_EnableIRQ(EXTI0_IRQn);

  HAL_NVIC_SetPriority(EXTI4_IRQn, 0, 0);
  HAL_NVIC_EnableIRQ(EXTI4_IRQn);

}

/* FSMC initialization function */
static void MX_FSMC_Init(void)
{

  FSMC_NORSRAM_TimingTypeDef Timing = {0};

  /** Perform the SRAM1 memory initialization sequence
  */
  hsram1.Instance = FSMC_NORSRAM_DEVICE;
  hsram1.Extended = FSMC_NORSRAM_EXTENDED_DEVICE;
  /* hsram1.Init */
  hsram1.Init.NSBank = FSMC_NORSRAM_BANK1;
  hsram1.Init.DataAddressMux = FSMC_DATA_ADDRESS_MUX_DISABLE;
  hsram1.Init.MemoryType = FSMC_MEMORY_TYPE_SRAM;
  hsram1.Init.MemoryDataWidth = FSMC_NORSRAM_MEM_BUS_WIDTH_16;
  hsram1.Init.BurstAccessMode = FSMC_BURST_ACCESS_MODE_DISABLE;
  hsram1.Init.WaitSignalPolarity = FSMC_WAIT_SIGNAL_POLARITY_LOW;
  hsram1.Init.WrapMode = FSMC_WRAP_MODE_DISABLE;
  hsram1.Init.WaitSignalActive = FSMC_WAIT_TIMING_BEFORE_WS;
  hsram1.Init.WriteOperation = FSMC_WRITE_OPERATION_ENABLE;
  hsram1.Init.WaitSignal = FSMC_WAIT_SIGNAL_DISABLE;
  hsram1.Init.ExtendedMode = FSMC_EXTENDED_MODE_DISABLE;
  hsram1.Init.AsynchronousWait = FSMC_ASYNCHRONOUS_WAIT_DISABLE;
  hsram1.Init.WriteBurst = FSMC_WRITE_BURST_DISABLE;
  /* Timing */
  Timing.AddressSetupTime = 15;
  Timing.AddressHoldTime = 15;
  Timing.DataSetupTime = 255;
  Timing.BusTurnAroundDuration = 15;
  Timing.CLKDivision = 16;
  Timing.DataLatency = 17;
  Timing.AccessMode = FSMC_ACCESS_MODE_A;
  /* ExtTiming */

  if (HAL_SRAM_Init(&hsram1, &Timing, NULL) != HAL_OK)
  {
    Error_Handler( );
  }

  /** Disconnect NADV
  */

  __HAL_AFIO_FSMCNADV_DISCONNECTED();

}

/* USER CODE BEGIN 4 */
void HAL_TIM_PeriodElapsedCallback(TIM_HandleTypeDef *htim){	//one second timer for timer3
	//HAL_GPIO_TogglePin(GPIOB, GPIO_PIN_1);
	if (timer >= 0) {
		print_digit(timer);
		timer--;
	}
	if (duration >= 0) duration++;
}

/* USER CODE END 4 */

void Error_Handler(void)
{
  __disable_irq();
  while (1)
  {
  }
}
